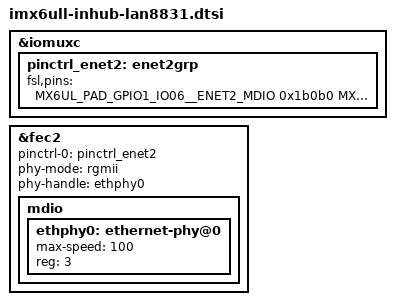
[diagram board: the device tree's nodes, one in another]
// SPDX-License-Identifier: GPL-2.0-only
/*
 * Copyright 2025 in.hub GmbH
 */

&iomuxc {
	/delete-node/ enet2-grp;

	pinctrl_enet2: enet2grp {
		fsl,pins = <
			MX6UL_PAD_GPIO1_IO06__ENET2_MDIO	0x1b0b0
			MX6UL_PAD_GPIO1_IO07__ENET2_MDC		0x1b0b0
			MX6UL_PAD_ENET2_RX_DATA0__ENET2_RDATA00	0x1b0b0
			MX6UL_PAD_ENET2_RX_DATA1__ENET2_RDATA01	0x1b0b0
			MX6UL_PAD_UART3_TX_DATA__ENET2_RDATA02	0x1b0b0
			MX6UL_PAD_UART3_RX_DATA__ENET2_RDATA03  0x1b0b0
			MX6UL_PAD_ENET2_RX_EN__ENET2_RX_EN	0x1b0b0
			MX6UL_PAD_ENET2_TX_CLK__ENET2_TX_CLK 0x1b0b0
			MX6UL_PAD_ENET2_TX_DATA0__ENET2_TDATA00	0x1b0b0
			MX6UL_PAD_ENET2_TX_DATA1__ENET2_TDATA01	0x1b0b0
			MX6UL_PAD_UART4_TX_DATA__ENET2_TDATA02	0x1b0b0
			MX6UL_PAD_UART4_RX_DATA__ENET2_TDATA03	0x1b0b0
			MX6UL_PAD_ENET2_TX_EN__ENET2_TX_EN	0x1b0b0
			MX6UL_PAD_UART3_CTS_B__ENET2_RX_CLK		0x1b0b0
			MX6UL_PAD_LCD_DATA16__GPIO3_IO21 0x1b0b0
			MX6UL_PAD_ENET2_RX_ER__ENET2_RX_ER	0x1b0b0
			MX6UL_PAD_UART5_RX_DATA__ENET2_COL	0x1b0b0
			MX6UL_PAD_UART5_TX_DATA__ENET2_CRS	0x1b0b0
		>;
	};
};

&fec2 {
	pinctrl-names = "default";
	pinctrl-0 = <&pinctrl_enet2>;
	phy-mode = "rgmii";
	phy-handle = <&ethphy0>;
	status = "okay";

	mdio {
		#address-cells = <1>;
		#size-cells = <0>;

		/delete-node/ ethernet-phy@2;

		ethphy0: ethernet-phy@0 {
			max-speed = <100>;
			reg = <3>;
		};
	};
};
